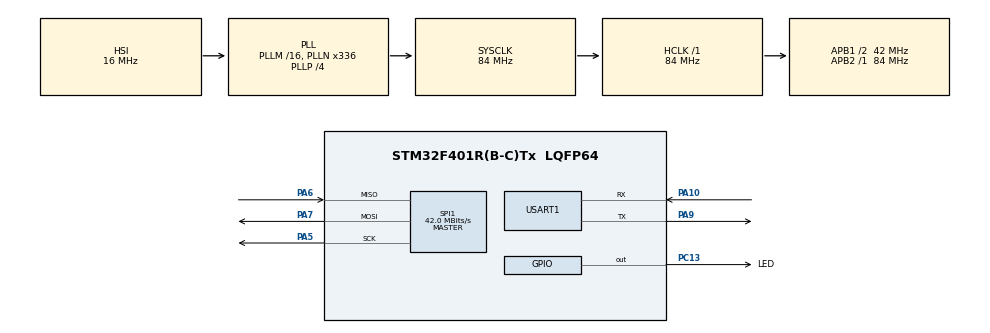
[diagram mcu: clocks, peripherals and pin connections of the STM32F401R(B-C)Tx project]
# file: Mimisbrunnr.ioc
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Dma.Request0=SPI1_TX
Dma.SPI1_TX.0.Direction=DMA_MEMORY_TO_PERIPH
Dma.SPI1_TX.0.FIFOMode=DMA_FIFOMODE_DISABLE
Dma.SPI1_TX.0.Instance=DMA2_Stream3
Dma.SPI1_TX.0.MemDataAlignment=DMA_MDATAALIGN_BYTE
Dma.SPI1_TX.0.MemInc=DMA_MINC_ENABLE
Dma.SPI1_TX.0.Mode=DMA_NORMAL
Dma.SPI1_TX.0.PeriphDataAlignment=DMA_PDATAALIGN_BYTE
Dma.SPI1_TX.0.PeriphInc=DMA_PINC_DISABLE
Dma.SPI1_TX.0.Priority=DMA_PRIORITY_LOW
Mcu.Family=STM32F4
Mcu.Name=STM32F401R(B-C)Tx
Mcu.Package=LQFP64
NVIC.DMA2_Stream3_IRQn=true\:0\:0\:false\:false\:true\:false\:true\:true
NVIC.PriorityGroup=NVIC_PRIORITYGROUP_4
NVIC.SPI1_IRQn=true\:0\:0\:false\:false\:true\:true\:true\:true
PA10.Mode=Asynchronous
PA10.Signal=USART1_RX
PA5.Mode=Full_Duplex_Master
PA5.Signal=SPI1_SCK
PA6.Mode=Full_Duplex_Master
PA6.Signal=SPI1_MISO
PA7.Mode=Full_Duplex_Master
PA7.Signal=SPI1_MOSI
PA9.Mode=Asynchronous
PA9.Signal=USART1_TX
PC13-ANTI_TAMP.GPIO_Label=LED
PC13-ANTI_TAMP.Signal=GPIO_Output
ProjectManager.HeapSize=0x200
ProjectManager.StackSize=0x400
ProjectManager.TargetToolchain=STM32CubeIDE
RCC.48MHZClocksFreq_Value=84000000
RCC.AHBFreq_Value=84000000
RCC.APB1CLKDivider=RCC_HCLK_DIV2
RCC.APB1Freq_Value=42000000
RCC.APB1TimFreq_Value=84000000
RCC.APB2Freq_Value=84000000
RCC.APB2TimFreq_Value=84000000
RCC.CortexFreq_Value=84000000
RCC.HCLKFreq_Value=84000000
RCC.HSE_VALUE=25000000
RCC.HSI_VALUE=16000000
RCC.LSE_VALUE=32768
RCC.PLLN=336
RCC.PLLP=RCC_PLLP_DIV4
RCC.SYSCLKFreq_VALUE=84000000
RCC.SYSCLKSource=RCC_SYSCLKSOURCE_PLLCLK
RCC.VCOOutputFreq_Value=336000000
SPI1.BaudRatePrescaler=SPI_BAUDRATEPRESCALER_2
SPI1.CalculateBaudRate=42.0 MBits/s
SPI1.Direction=SPI_DIRECTION_2LINES
SPI1.Mode=SPI_MODE_MASTER
SPI1.VirtualType=VM_MASTER
STMicroelectronics.X-CUBE-TOUCHGFX.4.22.1.ApplicationCcGraphicsJjApplication=TouchGFXOoGenerator
STMicroelectronics.X-CUBE-TOUCHGFX.4.22.1.tgfx_buffering_strategy=Single
STMicroelectronics.X-CUBE-TOUCHGFX.4.22.1.tgfx_oswrapper=NoOS
STMicroelectronics.X-CUBE-TOUCHGFX.4.22.1_IsPackSelfContextualization=true
USART1.VirtualMode=VM_ASYNC
VP_CRC_VS_CRC.Mode=CRC_Activate
VP_STMicroelectronics.X-CUBE-TOUCHGFX_VS_GraphicsJjApplication_4.22.1.Mode=GraphicsJjApplication
board=custom

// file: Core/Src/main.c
/* USER CODE BEGIN Header */
/**
  ******************************************************************************
  * @file           : main.c
  * @brief          : Main program body
  ******************************************************************************
  * @attention
  *
  * Copyright (c) 2024 STMicroelectronics.
  * All rights reserved.
  *
  * This software is licensed under terms that can be found in the LICENSE file
  * in the root directory of this software component.
  * If no LICENSE file comes with this software, it is provided AS-IS.
  *
  ******************************************************************************
  */
/* USER CODE END Header */
#include "main.h"
#include "app_touchgfx.h"

/* USER CODE BEGIN Includes */
#include "lvgl.h"
#include "lv_port_disp.h"
/* USER CODE END Includes */

CRC_HandleTypeDef hcrc;

SPI_HandleTypeDef hspi1;
DMA_HandleTypeDef hdma_spi1_tx;

UART_HandleTypeDef huart1;

void SystemClock_Config(void);
static void MX_GPIO_Init(void);
static void MX_DMA_Init(void);
static void MX_SPI1_Init(void);
static void MX_USART1_UART_Init(void);
static void MX_CRC_Init(void);

int main(void)
{

  /* MCU Configuration--------------------------------------------------------*/

  /* Reset of all peripherals, Initializes the Flash interface and the Systick. */
  HAL_Init();

  /* Configure the system clock */
  SystemClock_Config();

  /* Initialize all configured peripherals */
  MX_GPIO_Init();
  MX_DMA_Init();
  MX_SPI1_Init();
  MX_USART1_UART_Init();
  MX_CRC_Init();
  MX_TouchGFX_Init();
  /* USER CODE BEGIN 2 */
  lv_init();
  lv_port_disp_init();

  // Change the active screen's background color
 /* lv_obj_set_style_bg_color(lv_screen_active(), lv_color_hex(0x003a57), LV_PART_MAIN);
  lv_obj_set_style_text_color(lv_screen_active(), lv_color_hex(0xffffff), LV_PART_MAIN);

  Create a spinner
  lv_obj_t * spinner = lv_spinner_create(lv_screen_active(), 1000, 60);
  lv_obj_set_size(spinner, 64, 64);
  lv_obj_align(spinner, LV_ALIGN_BOTTOM_MID, 0, 0)*/;

  /* USER CODE END 2 */

  /* Infinite loop */
  while (1)
  {

  MX_TouchGFX_Process();
    /* USER CODE BEGIN 3 */
	  /*HAL_Delay(500);
	  HAL_GPIO_WritePin(LED_GPIO_Port, LED_Pin, 1);
	  HAL_Delay(500);
	  HAL_GPIO_WritePin(LED_GPIO_Port, LED_Pin, 0);*/

	  lv_timer_handler();
	  HAL_Delay(5);
  }
  /* USER CODE END 3 */
}

void SystemClock_Config(void)
{
  RCC_OscInitTypeDef RCC_OscInitStruct = {0};
  RCC_ClkInitTypeDef RCC_ClkInitStruct = {0};

  /** Configure the main internal regulator output voltage
  */
  __HAL_RCC_PWR_CLK_ENABLE();
  __HAL_PWR_VOLTAGESCALING_CONFIG(PWR_REGULATOR_VOLTAGE_SCALE2);

  /** Initializes the RCC Oscillators according to the specified parameters
  * in the RCC_OscInitTypeDef structure.
  */
  RCC_OscInitStruct.OscillatorType = RCC_OSCILLATORTYPE_HSI;
  RCC_OscInitStruct.HSIState = RCC_HSI_ON;
  RCC_OscInitStruct.HSICalibrationValue = RCC_HSICALIBRATION_DEFAULT;
  RCC_OscInitStruct.PLL.PLLState = RCC_PLL_ON;
  RCC_OscInitStruct.PLL.PLLSource = RCC_PLLSOURCE_HSI;
  RCC_OscInitStruct.PLL.PLLM = 16;
  RCC_OscInitStruct.PLL.PLLN = 336;
  RCC_OscInitStruct.PLL.PLLP = RCC_PLLP_DIV4;
  RCC_OscInitStruct.PLL.PLLQ = 4;
  if (HAL_RCC_OscConfig(&RCC_OscInitStruct) != HAL_OK)
  {
    Error_Handler();
  }

  /** Initializes the CPU, AHB and APB buses clocks
  */
  RCC_ClkInitStruct.ClockType = RCC_CLOCKTYPE_HCLK|RCC_CLOCKTYPE_SYSCLK
                              |RCC_CLOCKTYPE_PCLK1|RCC_CLOCKTYPE_PCLK2;
  RCC_ClkInitStruct.SYSCLKSource = RCC_SYSCLKSOURCE_PLLCLK;
  RCC_ClkInitStruct.AHBCLKDivider = RCC_SYSCLK_DIV1;
  RCC_ClkInitStruct.APB1CLKDivider = RCC_HCLK_DIV2;
  RCC_ClkInitStruct.APB2CLKDivider = RCC_HCLK_DIV1;

  if (HAL_RCC_ClockConfig(&RCC_ClkInitStruct, FLASH_LATENCY_2) != HAL_OK)
  {
    Error_Handler();
  }
}

static void MX_CRC_Init(void)
{

  hcrc.Instance = CRC;
  if (HAL_CRC_Init(&hcrc) != HAL_OK)
  {
    Error_Handler();
  }

}

static void MX_SPI1_Init(void)
{

  /* SPI1 parameter configuration*/
  hspi1.Instance = SPI1;
  hspi1.Init.Mode = SPI_MODE_MASTER;
  hspi1.Init.Direction = SPI_DIRECTION_2LINES;
  hspi1.Init.DataSize = SPI_DATASIZE_8BIT;
  hspi1.Init.CLKPolarity = SPI_POLARITY_LOW;
  hspi1.Init.CLKPhase = SPI_PHASE_1EDGE;
  hspi1.Init.NSS = SPI_NSS_SOFT;
  hspi1.Init.BaudRatePrescaler = SPI_BAUDRATEPRESCALER_2;
  hspi1.Init.FirstBit = SPI_FIRSTBIT_MSB;
  hspi1.Init.TIMode = SPI_TIMODE_DISABLE;
  hspi1.Init.CRCCalculation = SPI_CRCCALCULATION_DISABLE;
  hspi1.Init.CRCPolynomial = 10;
  if (HAL_SPI_Init(&hspi1) != HAL_OK)
  {
    Error_Handler();
  }

}

static void MX_USART1_UART_Init(void)
{

  huart1.Instance = USART1;
  huart1.Init.BaudRate = 115200;
  huart1.Init.WordLength = UART_WORDLENGTH_8B;
  huart1.Init.StopBits = UART_STOPBITS_1;
  huart1.Init.Parity = UART_PARITY_NONE;
  huart1.Init.Mode = UART_MODE_TX_RX;
  huart1.Init.HwFlowCtl = UART_HWCONTROL_NONE;
  huart1.Init.OverSampling = UART_OVERSAMPLING_16;
  if (HAL_UART_Init(&huart1) != HAL_OK)
  {
    Error_Handler();
  }

}

static void MX_DMA_Init(void)
{

  /* DMA controller clock enable */
  __HAL_RCC_DMA2_CLK_ENABLE();

  /* DMA interrupt init */
  /* DMA2_Stream3_IRQn interrupt configuration */
  HAL_NVIC_SetPriority(DMA2_Stream3_IRQn, 0, 0);
  HAL_NVIC_EnableIRQ(DMA2_Stream3_IRQn);

}

static void MX_GPIO_Init(void)
{
  GPIO_InitTypeDef GPIO_InitStruct = {0};

  /* GPIO Ports Clock Enable */
  __HAL_RCC_GPIOC_CLK_ENABLE();
  __HAL_RCC_GPIOA_CLK_ENABLE();

  /*Configure GPIO pin Output Level */
  HAL_GPIO_WritePin(LED_GPIO_Port, LED_Pin, GPIO_PIN_RESET);

  /*Configure GPIO pin : LED_Pin */
  GPIO_InitStruct.Pin = LED_Pin;
  GPIO_InitStruct.Mode = GPIO_MODE_OUTPUT_PP;
  GPIO_InitStruct.Pull = GPIO_NOPULL;
  GPIO_InitStruct.Speed = GPIO_SPEED_FREQ_LOW;
  HAL_GPIO_Init(LED_GPIO_Port, &GPIO_InitStruct);

}

void Error_Handler(void)
{
  __disable_irq();
  while (1)
  {
  }
}
